AUTOSAR XML (schema 4-0-3)
standard types defined: UInt32
package /PATAC/MSM/ComponentTypes
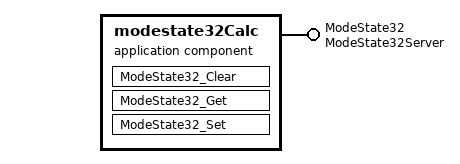
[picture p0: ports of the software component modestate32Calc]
  application sw component type modestate32Calc
    provide port ModeState32: provided-com-specs=[{operation=Clear, queue-length=1}, {operation=Get, queue-length=1}, {operation=Set, queue-length=1}], provided-interface=ModeState32Server
    behavior modestate32Calc_InternalBehavior
      operation invoked event OIT_ModeState32_Clear_ModeState32_Clear: start-on-event=ModeState32_Clear, operation=ModeState32.Clear
      operation invoked event OIT_ModeState32_Get_ModeState32_Get: start-on-event=ModeState32_Get, operation=ModeState32.Get
      operation invoked event OIT_ModeState32_Set_ModeState32_Set: start-on-event=ModeState32_Set, operation=ModeState32.Set
      runnable ModeState32_Clear
      runnable ModeState32_Get
      runnable ModeState32_Set
  swc implementation modestate32Calc_Implementation: behavior=modestate32Calc_InternalBehavior
    code-descriptors:
      code Default: artifact-descriptors=autosar-engineering-object={short-label=Default, category=SWSRC}
package /PATAC/MSM/ModeAdjust/PortInterface
  client server interface ModeState32Server
    operation Clear
      arg ClearBit: type=UInt32, direction=IN, server-argument-impl-policy=USE-ARGUMENT-TYPE
    operation Get
      arg MdEn32: type=UInt32, direction=OUT, server-argument-impl-policy=USE-ARGUMENT-TYPE
    operation Set
      arg SetBit: type=UInt32, direction=IN, server-argument-impl-policy=USE-ARGUMENT-TYPE
